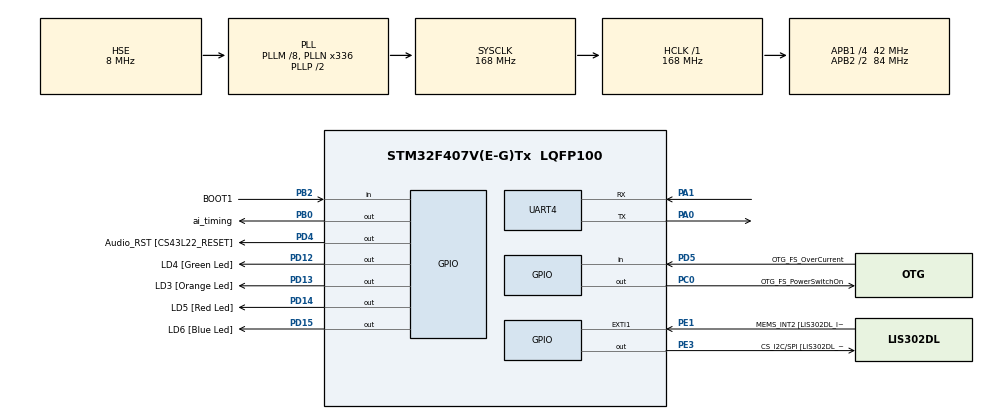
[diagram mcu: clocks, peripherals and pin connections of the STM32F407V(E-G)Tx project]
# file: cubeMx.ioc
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Mcu.Family=STM32F4
Mcu.Name=STM32F407V(E-G)Tx
Mcu.Package=LQFP100
NVIC.PriorityGroup=NVIC_PRIORITYGROUP_0
PA0-WKUP.Mode=Asynchronous
PA0-WKUP.Signal=UART4_TX
PA1.Mode=Asynchronous
PA1.Signal=UART4_RX
PA13.GPIO_Label=SWDIO
PA13.Mode=Serial_Wire
PA13.Signal=SYS_JTMS-SWDIO
PA14.GPIO_Label=SWCLK
PA14.Mode=Serial_Wire
PA14.Signal=SYS_JTCK-SWCLK
PB0.GPIO_Label=ai_timing
PB0.GPIO_Speed=GPIO_SPEED_FREQ_VERY_HIGH
PB0.Signal=GPIO_Output
PB2.GPIO_Label=BOOT1
PB2.GPIO_Mode=GPIO_MODE_INPUT
PB2.GPIO_PuPd=GPIO_NOPULL
PB2.Signal=GPIO_Input
PC0.GPIO_Label=OTG_FS_PowerSwitchOn
PC0.GPIO_PuPd=GPIO_NOPULL
PC0.GPIO_Speed=GPIO_SPEED_FREQ_LOW
PC0.PinState=GPIO_PIN_SET
PC0.Signal=GPIO_Output
PC14-OSC32_IN.GPIO_Label=PC14-OSC32_IN
PC14-OSC32_IN.Mode=LSE-External-Oscillator
PC14-OSC32_IN.Signal=RCC_OSC32_IN
PC15-OSC32_OUT.GPIO_Label=PC15-OSC32_OUT
PC15-OSC32_OUT.Mode=LSE-External-Oscillator
PC15-OSC32_OUT.Signal=RCC_OSC32_OUT
PD12.GPIO_Label=LD4 [Green Led]
PD12.GPIO_PuPd=GPIO_NOPULL
PD12.GPIO_Speed=GPIO_SPEED_FREQ_LOW
PD12.Signal=GPIO_Output
PD13.GPIO_Label=LD3 [Orange Led]
PD13.GPIO_PuPd=GPIO_NOPULL
PD13.GPIO_Speed=GPIO_SPEED_FREQ_LOW
PD13.Signal=GPIO_Output
PD14.GPIO_Label=LD5 [Red Led]
PD14.GPIO_PuPd=GPIO_NOPULL
PD14.GPIO_Speed=GPIO_SPEED_FREQ_LOW
PD14.Signal=GPIO_Output
PD15.GPIO_Label=LD6 [Blue Led]
PD15.GPIO_PuPd=GPIO_NOPULL
PD15.GPIO_Speed=GPIO_SPEED_FREQ_LOW
PD15.Signal=GPIO_Output
PD4.GPIO_Label=Audio_RST [CS43L22_RESET]
PD4.GPIO_PuPd=GPIO_NOPULL
PD4.GPIO_Speed=GPIO_SPEED_FREQ_LOW
PD4.Signal=GPIO_Output
PD5.GPIO_Label=OTG_FS_OverCurrent
PD5.GPIO_Mode=GPIO_MODE_INPUT
PD5.GPIO_PuPd=GPIO_NOPULL
PD5.Signal=GPIO_Input
PE1.GPIO_Label=MEMS_INT2 [LIS302DL_INT2]
PE1.GPIO_ModeDefaultEXTI=GPIO_MODE_EVT_RISING
PE1.GPIO_PuPd=GPIO_NOPULL
PE1.Signal=GPXTI1
PE3.GPIO_Label=CS_I2C/SPI [LIS302DL_CS_I2C/SPI]
PE3.GPIO_PuPd=GPIO_NOPULL
PE3.GPIO_Speed=GPIO_SPEED_FREQ_LOW
PE3.Signal=GPIO_Output
PH0-OSC_IN.GPIO_Label=PH0-OSC_IN
PH0-OSC_IN.Mode=HSE-External-Oscillator
PH0-OSC_IN.Signal=RCC_OSC_IN
PH1-OSC_OUT.GPIO_Label=PH1-OSC_OUT
PH1-OSC_OUT.Mode=HSE-External-Oscillator
PH1-OSC_OUT.Signal=RCC_OSC_OUT
ProjectManager.HeapSize=0x200
ProjectManager.StackSize=0x400
ProjectManager.TargetToolchain=Makefile
RCC.48MHZClocksFreq_Value=48000000
RCC.AHBFreq_Value=168000000
RCC.APB1CLKDivider=RCC_HCLK_DIV4
RCC.APB1Freq_Value=42000000
RCC.APB1TimFreq_Value=84000000
RCC.APB2CLKDivider=RCC_HCLK_DIV2
RCC.APB2Freq_Value=84000000
RCC.APB2TimFreq_Value=168000000
RCC.CortexFreq_Value=168000000
RCC.HCLKFreq_Value=168000000
RCC.HSE_VALUE=8000000
RCC.HSI_VALUE=16000000
RCC.PLLM=8
RCC.PLLN=336
RCC.PLLQ=7
RCC.PLLSourceVirtual=RCC_PLLSOURCE_HSE
RCC.SYSCLKFreq_VALUE=168000000
RCC.SYSCLKSource=RCC_SYSCLKSOURCE_PLLCLK
RCC.VCOOutputFreq_Value=336000000
UART4.VirtualMode=Asynchronous
board=STM32F4DISCOVERY

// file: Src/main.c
/* USER CODE BEGIN Header */
/**
  ******************************************************************************
  * @file           : main.c
  * @brief          : Main program body
  ******************************************************************************
  ** This notice applies to any and all portions of this file
  * that are not between comment pairs USER CODE BEGIN and
  * USER CODE END. Other portions of this file, whether
  * inserted by the user or by software development tools
  * are owned by their respective copyright owners.
  *
  * COPYRIGHT(c) 2018 STMicroelectronics
  *
  * Redistribution and use in source and binary forms, with or without modification,
  * are permitted provided that the following conditions are met:
  *   1. Redistributions of source code must retain the above copyright notice,
  *      this list of conditions and the following disclaimer.
  *   2. Redistributions in binary form must reproduce the above copyright notice,
  *      this list of conditions and the following disclaimer in the documentation
  *      and/or other materials provided with the distribution.
  *   3. Neither the name of STMicroelectronics nor the names of its contributors
  *      may be used to endorse or promote products derived from this software
  *      without specific prior written permission.
  *
  * THIS SOFTWARE IS PROVIDED BY THE COPYRIGHT HOLDERS AND CONTRIBUTORS "AS IS"
  * AND ANY EXPRESS OR IMPLIED WARRANTIES, INCLUDING, BUT NOT LIMITED TO, THE
  * IMPLIED WARRANTIES OF MERCHANTABILITY AND FITNESS FOR A PARTICULAR PURPOSE ARE
  * DISCLAIMED. IN NO EVENT SHALL THE COPYRIGHT HOLDER OR CONTRIBUTORS BE LIABLE
  * FOR ANY DIRECT, INDIRECT, INCIDENTAL, SPECIAL, EXEMPLARY, OR CONSEQUENTIAL
  * DAMAGES (INCLUDING, BUT NOT LIMITED TO, PROCUREMENT OF SUBSTITUTE GOODS OR
  * SERVICES; LOSS OF USE, DATA, OR PROFITS; OR BUSINESS INTERRUPTION) HOWEVER
  * CAUSED AND ON ANY THEORY OF LIABILITY, WHETHER IN CONTRACT, STRICT LIABILITY,
  * OR TORT (INCLUDING NEGLIGENCE OR OTHERWISE) ARISING IN ANY WAY OUT OF THE USE
  * OF THIS SOFTWARE, EVEN IF ADVISED OF THE POSSIBILITY OF SUCH DAMAGE.
  *
  ******************************************************************************
  */
/* USER CODE END Header */

#include "main.h"

#define IMAGE_SIZE 28 * 28 /* MMNIST images have 28*28 pixels */
UART_HandleTypeDef huart4;

void SystemClock_Config(void);
static void MX_GPIO_Init(void);
static void MX_UART4_Init(void);

/* USER CODE END PFP */

int main(void)
{
  /* USER CODE BEGIN 1 */
  uint8_t c_cmd;
  float ip1_out[10];
  uint16_t i;
  /* buffers for the MNIST image */
  uint8_t inputPicture[IMAGE_SIZE];
  float f32_digitToClassify[IMAGE_SIZE];
  float max_val = -1;

  /* USER CODE END 1 */

  /* MCU Configuration--------------------------------------------------------*/

  /* Reset of all peripherals, Initializes the Flash interface and the Systick. */
  HAL_Init();

  /* Configure the system clock */
  SystemClock_Config();

  /* Initialize all configured peripherals */
  MX_GPIO_Init();
  MX_UART4_Init();

  /* Infinite loop */
  while (1)
  {

    /* receive command */
    if (HAL_UART_Receive(&huart4, &c_cmd, 1, 200) != HAL_OK)
    {
      continue;
    }
    switch (c_cmd - 0)
    {
      case 's':
       /* handshake: receive 's' return 'X' */
        c_cmd = 'X' + 0;
        HAL_UART_Transmit(&huart4, &c_cmd, 1, 1000);
        c_cmd = 1; /* Renesas */
        HAL_UART_Transmit(&huart4, &c_cmd, 1, 1000);
        break;

        case 'c':
          if (HAL_UART_Receive(&huart4, inputPicture, IMAGE_SIZE, 1000) == HAL_OK)
          {

            /* reset max val */
            max_val = -1;

            /* scale input into float */
            for (i = 0; i < IMAGE_SIZE; i++) {
              f32_digitToClassify[i] = (float)inputPicture[i] / 255;
            }

            /* start time measurement */
            HAL_GPIO_WritePin(GPIOB, ai_timing_Pin, GPIO_PIN_SET);

            /* run nn */
            dnn_compute(f32_digitToClassify, ip1_out);

            /* find max */
            for(i = 0; i < 10; i++)
            {
                if(max_val < ip1_out[i])
                {
                    max_val = ip1_out[i];
                    c_cmd = i;
                }
            }

            /* stop time measurement */
            HAL_GPIO_WritePin(GPIOB, ai_timing_Pin, GPIO_PIN_RESET);

            /* return the prediction */
            HAL_UART_Transmit(&huart4, &c_cmd, 1, 1000);
          }
          break;
    }

    /* */
  }
}

void SystemClock_Config(void)
{
  RCC_OscInitTypeDef RCC_OscInitStruct = {0};
  RCC_ClkInitTypeDef RCC_ClkInitStruct = {0};

  /** Configure the main internal regulator output voltage
  */
  __HAL_RCC_PWR_CLK_ENABLE();
  __HAL_PWR_VOLTAGESCALING_CONFIG(PWR_REGULATOR_VOLTAGE_SCALE1);
  /** Initializes the CPU, AHB and APB busses clocks
  */
  RCC_OscInitStruct.OscillatorType = RCC_OSCILLATORTYPE_HSE;
  RCC_OscInitStruct.HSEState = RCC_HSE_ON;
  RCC_OscInitStruct.PLL.PLLState = RCC_PLL_ON;
  RCC_OscInitStruct.PLL.PLLSource = RCC_PLLSOURCE_HSE;
  RCC_OscInitStruct.PLL.PLLM = 8;
  RCC_OscInitStruct.PLL.PLLN = 336;
  RCC_OscInitStruct.PLL.PLLP = RCC_PLLP_DIV2;
  RCC_OscInitStruct.PLL.PLLQ = 7;
  if (HAL_RCC_OscConfig(&RCC_OscInitStruct) != HAL_OK)
  {
    Error_Handler();
  }
  /** Initializes the CPU, AHB and APB busses clocks
  */
  RCC_ClkInitStruct.ClockType = RCC_CLOCKTYPE_HCLK|RCC_CLOCKTYPE_SYSCLK
                              |RCC_CLOCKTYPE_PCLK1|RCC_CLOCKTYPE_PCLK2;
  RCC_ClkInitStruct.SYSCLKSource = RCC_SYSCLKSOURCE_PLLCLK;
  RCC_ClkInitStruct.AHBCLKDivider = RCC_SYSCLK_DIV1;
  RCC_ClkInitStruct.APB1CLKDivider = RCC_HCLK_DIV4;
  RCC_ClkInitStruct.APB2CLKDivider = RCC_HCLK_DIV2;

  if (HAL_RCC_ClockConfig(&RCC_ClkInitStruct, FLASH_LATENCY_5) != HAL_OK)
  {
    Error_Handler();
  }
}

static void MX_UART4_Init(void)
{

  huart4.Instance = UART4;
  huart4.Init.BaudRate = 256000;
  huart4.Init.WordLength = UART_WORDLENGTH_8B;
  huart4.Init.StopBits = UART_STOPBITS_1;
  huart4.Init.Parity = UART_PARITY_NONE;
  huart4.Init.Mode = UART_MODE_TX_RX;
  huart4.Init.HwFlowCtl = UART_HWCONTROL_NONE;
  huart4.Init.OverSampling = UART_OVERSAMPLING_16;
  if (HAL_UART_Init(&huart4) != HAL_OK)
  {
    Error_Handler();
  }

}

static void MX_GPIO_Init(void)
{
  GPIO_InitTypeDef GPIO_InitStruct = {0};

  /* GPIO Ports Clock Enable */
  __HAL_RCC_GPIOE_CLK_ENABLE();
  __HAL_RCC_GPIOC_CLK_ENABLE();
  __HAL_RCC_GPIOH_CLK_ENABLE();
  __HAL_RCC_GPIOA_CLK_ENABLE();
  __HAL_RCC_GPIOB_CLK_ENABLE();
  __HAL_RCC_GPIOD_CLK_ENABLE();

  /*Configure GPIO pin Output Level */
  HAL_GPIO_WritePin(CS_I2C_SPI_GPIO_Port, CS_I2C_SPI_Pin, GPIO_PIN_RESET);

  /*Configure GPIO pin Output Level */
  HAL_GPIO_WritePin(OTG_FS_PowerSwitchOn_GPIO_Port, OTG_FS_PowerSwitchOn_Pin, GPIO_PIN_SET);

  /*Configure GPIO pin Output Level */
  HAL_GPIO_WritePin(ai_timing_GPIO_Port, ai_timing_Pin, GPIO_PIN_RESET);

  /*Configure GPIO pin Output Level */
  HAL_GPIO_WritePin(GPIOD, LD4_Pin|LD3_Pin|LD5_Pin|LD6_Pin
                          |Audio_RST_Pin, GPIO_PIN_RESET);

  /*Configure GPIO pins : PE2 PE4 PE5 PE6
                           PE7 PE8 PE9 PE10
                           PE11 PE12 PE13 PE14
                           PE15 PE0 */
  GPIO_InitStruct.Pin = GPIO_PIN_2|GPIO_PIN_4|GPIO_PIN_5|GPIO_PIN_6
                          |GPIO_PIN_7|GPIO_PIN_8|GPIO_PIN_9|GPIO_PIN_10
                          |GPIO_PIN_11|GPIO_PIN_12|GPIO_PIN_13|GPIO_PIN_14
                          |GPIO_PIN_15|GPIO_PIN_0;
  GPIO_InitStruct.Mode = GPIO_MODE_ANALOG;
  GPIO_InitStruct.Pull = GPIO_NOPULL;
  HAL_GPIO_Init(GPIOE, &GPIO_InitStruct);

  /*Configure GPIO pin : CS_I2C_SPI_Pin */
  GPIO_InitStruct.Pin = CS_I2C_SPI_Pin;
  GPIO_InitStruct.Mode = GPIO_MODE_OUTPUT_PP;
  GPIO_InitStruct.Pull = GPIO_NOPULL;
  GPIO_InitStruct.Speed = GPIO_SPEED_FREQ_LOW;
  HAL_GPIO_Init(CS_I2C_SPI_GPIO_Port, &GPIO_InitStruct);

  /*Configure GPIO pins : PC13 PC1 PC2 PC3
                           PC4 PC5 PC6 PC7
                           PC8 PC9 PC10 PC11
                           PC12 */
  GPIO_InitStruct.Pin = GPIO_PIN_13|GPIO_PIN_1|GPIO_PIN_2|GPIO_PIN_3
                          |GPIO_PIN_4|GPIO_PIN_5|GPIO_PIN_6|GPIO_PIN_7
                          |GPIO_PIN_8|GPIO_PIN_9|GPIO_PIN_10|GPIO_PIN_11
                          |GPIO_PIN_12;
  GPIO_InitStruct.Mode = GPIO_MODE_ANALOG;
  GPIO_InitStruct.Pull = GPIO_NOPULL;
  HAL_GPIO_Init(GPIOC, &GPIO_InitStruct);

  /*Configure GPIO pin : OTG_FS_PowerSwitchOn_Pin */
  GPIO_InitStruct.Pin = OTG_FS_PowerSwitchOn_Pin;
  GPIO_InitStruct.Mode = GPIO_MODE_OUTPUT_PP;
  GPIO_InitStruct.Pull = GPIO_NOPULL;
  GPIO_InitStruct.Speed = GPIO_SPEED_FREQ_LOW;
  HAL_GPIO_Init(OTG_FS_PowerSwitchOn_GPIO_Port, &GPIO_InitStruct);

  /*Configure GPIO pins : PA2 PA3 PA4 PA5
                           PA6 PA7 PA8 PA9
                           PA10 PA11 PA12 PA15 */
  GPIO_InitStruct.Pin = GPIO_PIN_2|GPIO_PIN_3|GPIO_PIN_4|GPIO_PIN_5
                          |GPIO_PIN_6|GPIO_PIN_7|GPIO_PIN_8|GPIO_PIN_9
                          |GPIO_PIN_10|GPIO_PIN_11|GPIO_PIN_12|GPIO_PIN_15;
  GPIO_InitStruct.Mode = GPIO_MODE_ANALOG;
  GPIO_InitStruct.Pull = GPIO_NOPULL;
  HAL_GPIO_Init(GPIOA, &GPIO_InitStruct);

  /*Configure GPIO pin : ai_timing_Pin */
  GPIO_InitStruct.Pin = ai_timing_Pin;
  GPIO_InitStruct.Mode = GPIO_MODE_OUTPUT_PP;
  GPIO_InitStruct.Pull = GPIO_NOPULL;
  GPIO_InitStruct.Speed = GPIO_SPEED_FREQ_VERY_HIGH;
  HAL_GPIO_Init(ai_timing_GPIO_Port, &GPIO_InitStruct);

  /*Configure GPIO pins : PB1 PB10 PB11 PB12
                           PB13 PB14 PB15 PB3
                           PB4 PB5 PB6 PB7
                           PB8 PB9 */
  GPIO_InitStruct.Pin = GPIO_PIN_1|GPIO_PIN_10|GPIO_PIN_11|GPIO_PIN_12
                          |GPIO_PIN_13|GPIO_PIN_14|GPIO_PIN_15|GPIO_PIN_3
                          |GPIO_PIN_4|GPIO_PIN_5|GPIO_PIN_6|GPIO_PIN_7
                          |GPIO_PIN_8|GPIO_PIN_9;
  GPIO_InitStruct.Mode = GPIO_MODE_ANALOG;
  GPIO_InitStruct.Pull = GPIO_NOPULL;
  HAL_GPIO_Init(GPIOB, &GPIO_InitStruct);

  /*Configure GPIO pin : BOOT1_Pin */
  GPIO_InitStruct.Pin = BOOT1_Pin;
  GPIO_InitStruct.Mode = GPIO_MODE_INPUT;
  GPIO_InitStruct.Pull = GPIO_NOPULL;
  HAL_GPIO_Init(BOOT1_GPIO_Port, &GPIO_InitStruct);

  /*Configure GPIO pins : PD8 PD9 PD10 PD11
                           PD0 PD1 PD2 PD3
                           PD6 PD7 */
  GPIO_InitStruct.Pin = GPIO_PIN_8|GPIO_PIN_9|GPIO_PIN_10|GPIO_PIN_11
                          |GPIO_PIN_0|GPIO_PIN_1|GPIO_PIN_2|GPIO_PIN_3
                          |GPIO_PIN_6|GPIO_PIN_7;
  GPIO_InitStruct.Mode = GPIO_MODE_ANALOG;
  GPIO_InitStruct.Pull = GPIO_NOPULL;
  HAL_GPIO_Init(GPIOD, &GPIO_InitStruct);

  /*Configure GPIO pins : LD4_Pin LD3_Pin LD5_Pin LD6_Pin
                           Audio_RST_Pin */
  GPIO_InitStruct.Pin = LD4_Pin|LD3_Pin|LD5_Pin|LD6_Pin
                          |Audio_RST_Pin;
  GPIO_InitStruct.Mode = GPIO_MODE_OUTPUT_PP;
  GPIO_InitStruct.Pull = GPIO_NOPULL;
  GPIO_InitStruct.Speed = GPIO_SPEED_FREQ_LOW;
  HAL_GPIO_Init(GPIOD, &GPIO_InitStruct);

  /*Configure GPIO pin : OTG_FS_OverCurrent_Pin */
  GPIO_InitStruct.Pin = OTG_FS_OverCurrent_Pin;
  GPIO_InitStruct.Mode = GPIO_MODE_INPUT;
  GPIO_InitStruct.Pull = GPIO_NOPULL;
  HAL_GPIO_Init(OTG_FS_OverCurrent_GPIO_Port, &GPIO_InitStruct);

  /*Configure GPIO pin : MEMS_INT2_Pin */
  GPIO_InitStruct.Pin = MEMS_INT2_Pin;
  GPIO_InitStruct.Mode = GPIO_MODE_EVT_RISING;
  GPIO_InitStruct.Pull = GPIO_NOPULL;
  HAL_GPIO_Init(MEMS_INT2_GPIO_Port, &GPIO_InitStruct);

}

void Error_Handler(void)
{
}

/************************ (C) COPYRIGHT STMicroelectronics *****END OF FILE****/
